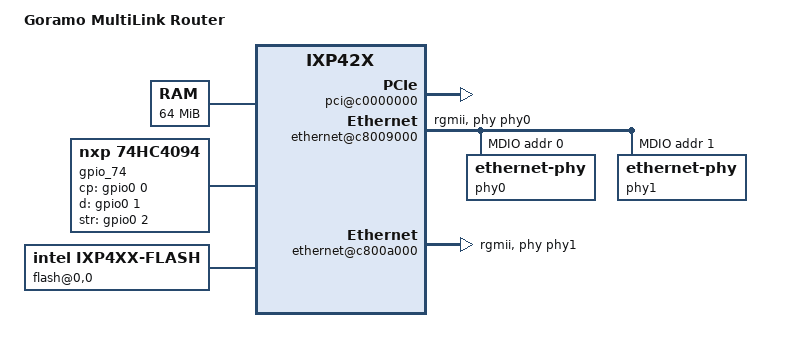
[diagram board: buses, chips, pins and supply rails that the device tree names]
/dts-v1/;
#include "intel-ixp42x.dtsi"
#include <dt-bindings/input/input.h>
/ {
	model = "Goramo MultiLink Router";
	compatible = "goramo,multilink-router", "intel,ixp42x";
	#address-cells = <1>;
	#size-cells = <1>;
	memory@0 {
		device_type = "memory";
		reg = <0x00000000 0x4000000>;
	};
	chosen {
		bootargs = "console=ttyS0,115200n8";
		stdout-path = "uart0:115200n8";
	};
	aliases {
		serial0 = &uart0;
		serial1 = &uart1;
	};
	gpio_74: gpio-74hc4094 {
		compatible = "nxp,74hc4094";
		cp-gpios = <&gpio0 0 GPIO_ACTIVE_HIGH>;
		d-gpios = <&gpio0 1 GPIO_ACTIVE_HIGH>;
		str-gpios = <&gpio0 2 GPIO_ACTIVE_HIGH>;
		gpio-controller;
		#gpio-cells = <2>;
		registers-number = <1>;
		gpio-line-names = "CONTROL_HSS0_CLK_INT", "CONTROL_HSS1_CLK_INT", "CONTROL_HSS0_DTR_N",
				"CONTROL_HSS1_DTR_N", "CONTROL_EXT", "CONTROL_AUTO_RESET",
				"CONTROL_PCI_RESET_N", "CONTROL_EEPROM_WC_N";
	};
	soc {
		bus@c4000000 {
			flash@0,0 {
				compatible = "intel,ixp4xx-flash", "cfi-flash";
				bank-width = <2>;
				intel,ixp4xx-eb-write-enable = <1>;
				reg = <0 0x00000000 0x1000000>;
				partitions {
					compatible = "redboot-fis";
					fis-index-block = <0x7f>;
				};
			};
		};
		pci@c0000000 {
			status = "okay";
			interrupt-map =
			<0x5800 0 0 1 &gpio0 4 IRQ_TYPE_LEVEL_LOW>,  
			<0x5800 0 0 2 &gpio0 4 IRQ_TYPE_LEVEL_LOW>,  
			<0x5800 0 0 3 &gpio0 4 IRQ_TYPE_LEVEL_LOW>,  
			<0x5800 0 0 4 &gpio0 4 IRQ_TYPE_LEVEL_LOW>,  
			<0x6000 0 0 1 &gpio0 5 IRQ_TYPE_LEVEL_LOW>,  
			<0x6000 0 0 2 &gpio0 5 IRQ_TYPE_LEVEL_LOW>,  
			<0x6000 0 0 3 &gpio0 5 IRQ_TYPE_LEVEL_LOW>,  
			<0x6000 0 0 4 &gpio0 5 IRQ_TYPE_LEVEL_LOW>,  
			<0x6800 0 0 1 &gpio0 12 IRQ_TYPE_LEVEL_LOW>,  
			<0x6800 0 0 2 &gpio0 12 IRQ_TYPE_LEVEL_LOW>,  
			<0x6800 0 0 3 &gpio0 12 IRQ_TYPE_LEVEL_LOW>,  
			<0x6800 0 0 4 &gpio0 12 IRQ_TYPE_LEVEL_LOW>,  
			<0x7000 0 0 1 &gpio0 3 IRQ_TYPE_LEVEL_LOW>,  
			<0x7000 0 0 2 &gpio0 3 IRQ_TYPE_LEVEL_LOW>,  
			<0x7000 0 0 3 &gpio0 3 IRQ_TYPE_LEVEL_LOW>,  
			<0x7000 0 0 4 &gpio0 3 IRQ_TYPE_LEVEL_LOW>;  
		};
		npe@c8006000 {
			hss@0 {
				status = "okay";
				intel,queue-chl-rxtrig = <&qmgr 12>;
				intel,queue-chl-txready = <&qmgr 34>;
				intel,queue-pkt-rx = <&qmgr 13>;
				intel,queue-pkt-tx = <&qmgr 14>, <&qmgr 15>, <&qmgr 16>, <&qmgr 17>;
				intel,queue-pkt-rxfree = <&qmgr 18>, <&qmgr 19>, <&qmgr 20>, <&qmgr 21>;
				intel,queue-pkt-txdone = <&qmgr 22>;
				cts-gpios = <&gpio0 10 GPIO_ACTIVE_LOW>;
				rts-gpios = <&gpio0 14 GPIO_ACTIVE_LOW>;
				dcd-gpios = <&gpio0 6 GPIO_ACTIVE_LOW>;
				dtr-gpios = <&gpio_74 2 GPIO_ACTIVE_LOW>;
				clk-internal-gpios = <&gpio_74 0 GPIO_ACTIVE_HIGH>;
			};
			hss@1 {
				status = "okay";
				intel,queue-chl-rxtrig = <&qmgr 10>;
				intel,queue-chl-txready = <&qmgr 35>;
				intel,queue-pkt-rx = <&qmgr 0>;
				intel,queue-pkt-tx = <&qmgr 5>, <&qmgr 6>, <&qmgr 7>, <&qmgr 8>;
				intel,queue-pkt-rxfree = <&qmgr 1>, <&qmgr 2>, <&qmgr 3>, <&qmgr 4>;
				intel,queue-pkt-txdone = <&qmgr 9>;
				cts-gpios = <&gpio0 11 GPIO_ACTIVE_LOW>;
				rts-gpios = <&gpio0 13 GPIO_ACTIVE_LOW>;
				dcd-gpios = <&gpio0 7 GPIO_ACTIVE_LOW>;
				dtr-gpios = <&gpio_74 3 GPIO_ACTIVE_LOW>;
				clk-internal-gpios = <&gpio_74 1 GPIO_ACTIVE_HIGH>;
			};
		};
		ethernet@c8009000 {
			status = "okay";
			queue-rx = <&qmgr 3>;
			queue-txready = <&qmgr 32>;
			phy-mode = "rgmii";
			phy-handle = <&phy0>;
			mdio {
				#address-cells = <1>;
				#size-cells = <0>;
				phy0: ethernet-phy@0 {
					reg = <0>;
				};
				phy1: ethernet-phy@1 {
					reg = <1>;
				};
			};
		};
		ethernet@c800a000 {
			status = "okay";
			queue-rx = <&qmgr 4>;
			queue-txready = <&qmgr 33>;
			phy-mode = "rgmii";
			phy-handle = <&phy1>;
		};
	};
};
